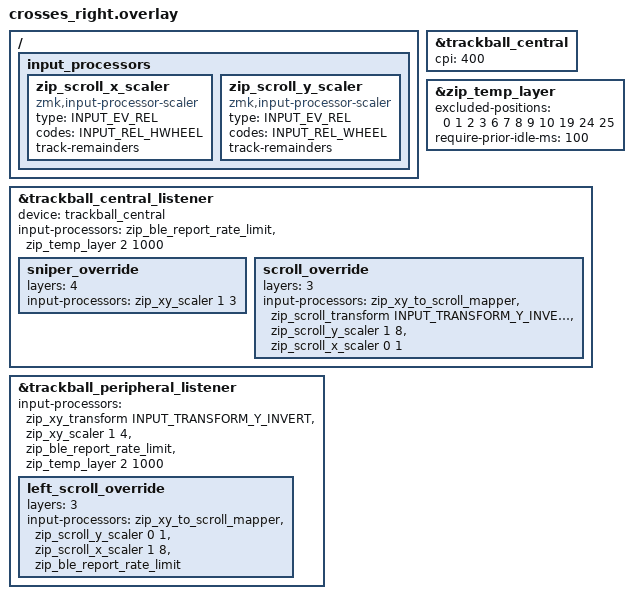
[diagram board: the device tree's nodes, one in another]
#include <zephyr/dt-bindings/input/input-event-codes.h>
#include <dt-bindings/zmk/input_transform.h>

&trackball_central {
    cpi = <400>; // 오른쪽 트랙볼 커서 속도. 빠르면 300, 느리면 600 정도로 조절.
};

/ {
    input_processors {
        // 가로 스크롤 전용 scaler.
        zip_scroll_x_scaler: zip_scroll_x_scaler {
            compatible = "zmk,input-processor-scaler";
            #input-processor-cells = <2>;
            type = <INPUT_EV_REL>;
            codes = <INPUT_REL_HWHEEL>;
            track-remainders;
        };

        // 세로 스크롤 전용 scaler.
        zip_scroll_y_scaler: zip_scroll_y_scaler {
            compatible = "zmk,input-processor-scaler";
            #input-processor-cells = <2>;
            type = <INPUT_EV_REL>;
            codes = <INPUT_REL_WHEEL>;
            track-remainders;
        };
    };
};

/*
 * 트랙볼을 움직이면 2번 Mouse 레이어로 자동 진입.
 *
 * excluded-positions는 Mouse 레이어가 켜진 상태에서 눌러도
 * 오토마우스 레이어가 꺼지면 안 되는 키 목록임.
 *
 * 현재 2번 Mouse 레이어 기준:
 * 0  = Q 자리 / LEFT_ALT
 * 1  = W 자리 / MCLK
 * 2  = E 자리 / RCLK
 * 3  = R 자리 / LCLK
 * 6  = U 자리 / LCLK
 * 7  = I 자리 / RCLK
 * 8  = O 자리 / MCLK
 * 9  = P 자리 / RIGHT_ALT
 * 10 = A 자리 / LSHFT
 * 19 = ; 자리 / RIGHT_SHIFT
 * 24 = B 자리 / LCTRL
 * 25 = N 자리 / RCTRL
 */
&zip_temp_layer {
    excluded-positions = <
        0
        1
        2
        3
        6
        7
        8
        9
        10
        19
        24
        25
    >;

    require-prior-idle-ms = <100>;
};

&trackball_central_listener {
    status = "okay";
    device = <&trackball_central>;

    input-processors = <
        &zip_ble_report_rate_limit
        &zip_temp_layer 2 1000
    >;

    sniper_override {
        layers = <4>;
        input-processors = <
            &zip_xy_scaler 1 3
        >;
    };

    scroll_override {
        layers = <3>;
        input-processors = <
            &zip_xy_to_scroll_mapper
            &zip_scroll_transform INPUT_TRANSFORM_Y_INVERT
            &zip_scroll_y_scaler 1 8
            &zip_scroll_x_scaler 0 1
        >;
    };
};

&trackball_peripheral_listener {
    status = "okay";

    /*
     * 왼쪽 트랙볼 기본 동작.
     *
     * 기본 레이어에서는 오른쪽 트랙볼처럼 커서 이동으로 사용함.
     * 왼쪽은 상하가 반대라 XY용 transform의 Y_INVERT로 보정.
     * 왼쪽 센서 CPI를 너무 낮추면 PMW3610 쪽이 먹통처럼 되는 경우가 있어서
     * 왼쪽 CPI는 crosses_left.overlay에서 400으로 고정하고 여기서 소프트웨어 감속함.
     * zip_xy_scaler 1 2 = 커서 속도 1/2. 더 느리게 하려면 1 3, 1 4.
     * 왼쪽 트랙볼을 움직여도 2번 Mouse 레이어로 진입해야 클릭키가 바로 먹음.
     * 여기서 scroll mapper를 빼야 평소에 마우스로 움직임.
     */
    input-processors = <
        &zip_xy_transform INPUT_TRANSFORM_Y_INVERT
        &zip_xy_scaler 1 4
        &zip_ble_report_rate_limit
        &zip_temp_layer 2 1000
    >;

    /*
     * 3번 Scroll 레이어에서 왼쪽 트랙볼을 가로 스크롤 전용으로 사용.
     *
     * zip_xy_to_scroll_mapper:
     * - X 이동 -> 가로 휠(INPUT_REL_HWHEEL)
     * - Y 이동 -> 세로 휠(INPUT_REL_WHEEL)
     *
     * 이 설정에서는 왼쪽 트랙볼을 좌우 스크롤 전용으로 쓰기 위해
     * 세로 휠은 zip_scroll_y_scaler 0 1로 죽이고,
     * 가로 휠만 zip_scroll_x_scaler 1 8로 살림.
     *
     * 방향:
     * - 기본 마우스 이동은 위에서 XY용 Y_INVERT로 따로 보정함.
     * - 스크롤 레이어는 mapper 뒤의 scroll Y_INVERT를 빼서 반대 방향 문제를 해결함.
     *
     * 감도:
     * - 1 8 = 입력값을 1/8로 줄임.
     * - 더 느리게 하려면 1 10, 1 12.
     * - 더 빠르게 하려면 1 6, 1 4.
     */
    left_scroll_override {
        layers = <3>;
        input-processors = <
            &zip_xy_to_scroll_mapper
            &zip_scroll_y_scaler 0 1
            &zip_scroll_x_scaler 1 8
            &zip_ble_report_rate_limit
        >;
    };
};
